AUTOSAR XML (schema 4-2-2)
package /Components
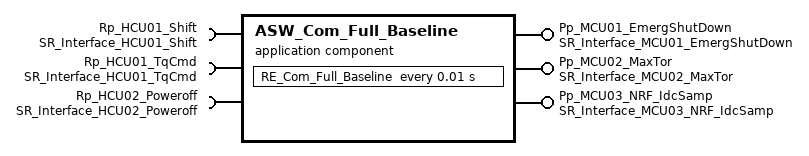
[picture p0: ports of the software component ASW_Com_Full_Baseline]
  application sw component type ASW_Com_Full_Baseline
    provide port Pp_MCU01_EmergShutDown: provided-interface=SR_Interface_MCU01_EmergShutDown
    provide port Pp_MCU02_MaxTor: provided-interface=SR_Interface_MCU02_MaxTor
    provide port Pp_MCU03_NRF_IdcSamp: provided-interface=SR_Interface_MCU03_NRF_IdcSamp
    require port Rp_HCU01_Shift: nonqueued-receiver-com-spec{data-element=HCU01_Shift, alive-timeout=0.3, init-value=0}, required-interface=SR_Interface_HCU01_Shift
    require port Rp_HCU01_TqCmd: nonqueued-receiver-com-spec{data-element=HCU01_TqCmd, alive-timeout=0.3, init-value=0}, required-interface=SR_Interface_HCU01_TqCmd
    require port Rp_HCU02_Poweroff: nonqueued-receiver-com-spec{data-element=HCU02_Poweroff, alive-timeout=0.3, init-value=0}, required-interface=SR_Interface_HCU02_Poweroff
    behavior IB_Com_Full_Baseline
      timing event TE_Com_Full_Baseline: start-on-event=RE_Com_Full_Baseline, period=0.01
      runnable RE_Com_Full_Baseline
        data-receive-point-by-arguments:
          access VA_Com_Full_Baseline_Read_HCU01_TqCmd: accessed-variable=Rp_HCU01_TqCmd.HCU01_TqCmd
          access VA_Com_Full_Baseline_Read_HCU01_Shift: accessed-variable=Rp_HCU01_Shift.HCU01_Shift
          access VA_Com_Full_Baseline_Read_HCU02_Poweroff: accessed-variable=Rp_HCU02_Poweroff.HCU02_Poweroff
        data-send-points:
          access VA_Com_Full_Baseline_Write_MCU01_EmergShutDown: accessed-variable=Pp_MCU01_EmergShutDown.MCU01_EmergShutDown
          access VA_Com_Full_Baseline_Write_MCU02_MaxTor: accessed-variable=Pp_MCU02_MaxTor.MCU02_MaxTor
          access VA_Com_Full_Baseline_Write_MCU03_NRF_IdcSamp: accessed-variable=Pp_MCU03_NRF_IdcSamp.MCU03_NRF_IdcSamp
